AUTOSAR XML (schema 4-0-3)
package /ComponentTypes
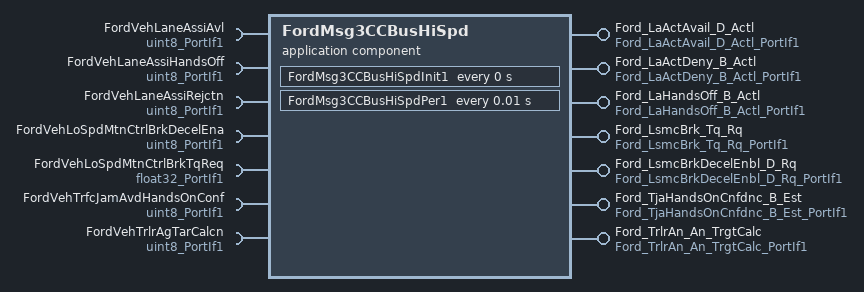
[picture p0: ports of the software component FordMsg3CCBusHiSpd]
  application sw component type FordMsg3CCBusHiSpd  # The purpose of the Ford Message 3CC Bus High Speed function is to transmit Electric Power Assisted Steering information to other vehicle modules
    7 x provide port:
      Ford_LaActAvail_D_Actl: nonqueued-sender-com-spec{data-element=Ford_LaActAvail_D_Actl, init-value=0}, provided-interface=Ford_LaActAvail_D_Actl_PortIf1  # Processed value of Ford_LaActAvail_D_Actl. Customer datatype should be used. Datatype:Ford_LaActAvail_D_Actl Elements are: 0 - "Cx0_LCA_LKA_LDW_Suppress", 1 - "Cx1_LCA_LKA_Suppress_LDW_Avail2 - "Cx2_LCA_LKA_Avail_LDW_Suppress", 3 - "Cx3_LKA_LCA_LDW_Avail"
      Ford_LaActDeny_B_Actl: nonqueued-sender-com-spec{data-element=Ford_LaActDeny_B_Actl, init-value=0}, provided-interface=Ford_LaActDeny_B_Actl_PortIf1  # Processed value of Ford_LaActDeny_B_Actl1. Customer datatype should be used. Datatype:Ford_LaActDeny_B_Actl. Elements are: 0 - "Cx0_LA_Not_Denied", 1 - "Cx1_LA_Denied
      Ford_LaHandsOff_B_Actl: nonqueued-sender-com-spec{data-element=Ford_LaHandsOff_B_Actl, init-value=1}, provided-interface=Ford_LaHandsOff_B_Actl_PortIf1  # Processed value of Ford_LaHandsOff_B_Actl. Customer datatype should be used. Datatype:Ford_LaHandsOff_B_Actl. Elements are: 0 - "Cx0_Hands_On", 1 - "Cx1_Hands_Off
      Ford_LsmcBrk_Tq_Rq: nonqueued-sender-com-spec{data-element=Ford_LsmcBrk_Tq_Rq, init-value=0}, provided-interface=Ford_LsmcBrk_Tq_Rq_PortIf1  # Processed value of Ford_LsmcBrk_Tq_Rq. Customer datatype should be used. Datatype:Ford_LsmcBrk_Tq_Rq with the range of 0 to 32764.
      Ford_LsmcBrkDecelEnbl_D_Rq: nonqueued-sender-com-spec{data-element=Ford_LsmcBrkDecelEnbl_D_Rq, init-value=0}, provided-interface=Ford_LsmcBrkDecelEnbl_D_Rq_PortIf1  # Processed value of Ford_LsmcBrkDecelEnbl_D_Rq. Customer datatype should be used. Datatype:Ford_LsmcBrkDecelEnbl_D_Rq. Elements are: 0 - "Cx0' _Off", 1 - "Cx1_On2 - "Cx2_NotUsed1", 3 - "Cx3_NotUsed2
      Ford_TjaHandsOnCnfdnc_B_Est: nonqueued-sender-com-spec{data-element=Ford_TjaHandsOnCnfdnc_B_Est, init-value=0}, provided-interface=Ford_TjaHandsOnCnfdnc_B_Est_PortIf1  # Processed value of Ford_TjaHandsOnCnfdnc_B_Est.Customer datatype should be used. Datatype:Ford_TjaHandsOnCnfdnc_B_Est1. Elements are: 0 - "C' x0_Low_Confidence", 1 - "Cx1_High_Confidence
      Ford_TrlrAn_An_TrgtCalc: nonqueued-sender-com-spec{data-element=Ford_TrlrAn_An_TrgtCalc, init-value=0}, provided-interface=Ford_TrlrAn_An_TrgtCalc_PortIf1  # Processed value of Ford_TrlrAn_An_TrgtCalc.Customer datatype should be used. Datatype:Ford_TrlrAn_An_TrgtCalc with the range of 0 to 255.
    7 x require port:
      FordVehLaneAssiAvl: nonqueued-receiver-com-spec{data-element=Val, filter=data-filter-type=ALWAYS, init-value=0}, required-interface=uint8_PortIf1  # Ford Vehicle Lane Assist Available is received as input from EPS and processed to CAN Bus
      FordVehLaneAssiHandsOff: nonqueued-receiver-com-spec{data-element=Val, filter=data-filter-type=ALWAYS, init-value=1}, required-interface=uint8_PortIf1  # Ford Vehicle Lane Assist Hands Off is received as input from EPS and processed to CAN Bus
      FordVehLaneAssiRejctn: nonqueued-receiver-com-spec{data-element=Val, filter=data-filter-type=ALWAYS, init-value=0}, required-interface=uint8_PortIf1  # Ford Vehicle Lane Assist Rejection is received as input from EPS and processed to CAN Bus
      FordVehLoSpdMtnCtrlBrkDecelEna: nonqueued-receiver-com-spec{data-element=Val, filter=data-filter-type=ALWAYS, init-value=0}, required-interface=uint8_PortIf1  # Ford Vehicle Low Speed Motion Control Brake Deceleration Enable is received as input from EPS and processed to CAN Bus
      FordVehLoSpdMtnCtrlBrkTqReq: nonqueued-receiver-com-spec{data-element=Val, filter=data-filter-type=ALWAYS, init-value=0}, required-interface=float32_PortIf1  # Ford Vehicle Low Speed Motion Control Brake Torque Request is received as input from EPS and processed to CAN Bus
      FordVehTrfcJamAvdHandsOnConf: nonqueued-receiver-com-spec{data-element=Val, filter=data-filter-type=ALWAYS, init-value=0}, required-interface=uint8_PortIf1  # Ford Vehicle Traffic Jam Avoidance Hands On Confidence is received as input from EPS and processed to CAN Bus
      FordVehTrlrAgTarCalcn: nonqueued-receiver-com-spec{data-element=Val, filter=data-filter-type=ALWAYS, init-value=0}, required-interface=uint8_PortIf1  # Ford Vehicle Trailer Angle Target Calculation is received as input from EPS and processed to CAN Bus
    behavior FordMsg3CCBusHiSpd_InternalBehavior
      timing event FordMsg3CCBusHiSpd_InitEvent: start-on-event=FordMsg3CCBusHiSpdInit1, period=0
      timing event TMT_FordMsg3CCBusHiSpdPer1: start-on-event=FordMsg3CCBusHiSpdPer1, period=0.01
      runnable FordMsg3CCBusHiSpdInit1  # Initialization Runnable
        data-send-points:
          access SEND_Ford_LaHandsOff_B_Actl_Ford_LaHandsOff_B_Actl: accessed-variable=Ford_LaHandsOff_B_Actl.Ford_LaHandsOff_B_Actl
      runnable FordMsg3CCBusHiSpdPer1: minimum-start-interval=0.01  # Periodic Runnable at 10ms
        data-receive-point-by-arguments:
          7 x access:
            REC_FordVehLaneAssiAvl_Val: accessed-variable=FordVehLaneAssiAvl.Val
            REC_FordVehLaneAssiHandsOff_Val: accessed-variable=FordVehLaneAssiHandsOff.Val
            REC_FordVehLaneAssiRejctn_Val: accessed-variable=FordVehLaneAssiRejctn.Val
            REC_FordVehLoSpdMtnCtrlBrkDecelEna_Val: accessed-variable=FordVehLoSpdMtnCtrlBrkDecelEna.Val
            REC_FordVehLoSpdMtnCtrlBrkTqReq_Val: accessed-variable=FordVehLoSpdMtnCtrlBrkTqReq.Val
            REC_FordVehTrfcJamAvdHandsOnConf_Val: accessed-variable=FordVehTrfcJamAvdHandsOnConf.Val
            REC_FordVehTrlrAgTarCalcn_Val: accessed-variable=FordVehTrlrAgTarCalcn.Val
        data-send-points:
          7 x access:
            SEND_Ford_LaActAvail_D_Actl1_Ford_LaActAvail_D_Actl: accessed-variable=Ford_LaActAvail_D_Actl.Ford_LaActAvail_D_Actl
            SEND_Ford_LaActDeny_B_Actl1_Ford_LaActDeny_B_Actl: accessed-variable=Ford_LaActDeny_B_Actl.Ford_LaActDeny_B_Actl
            SEND_Ford_LaHandsOff_B_Actl1_Ford_LaHandsOff_B_Actl: accessed-variable=Ford_LaHandsOff_B_Actl.Ford_LaHandsOff_B_Actl
            SEND_Ford_LsmcBrk_Tq_Rq_Ford_LsmcBrk_Tq_Rq: accessed-variable=Ford_LsmcBrk_Tq_Rq.Ford_LsmcBrk_Tq_Rq
            SEND_Ford_LsmcBrkDecelEnbl_D_Rq1_Ford_LsmcBrkDecelEnbl_D_Rq: accessed-variable=Ford_LsmcBrkDecelEnbl_D_Rq.Ford_LsmcBrkDecelEnbl_D_Rq
            SEND_Ford_TjaHandsOnCnfdnc_B_Est1_Ford_TjaHandsOnCnfdnc_B_Est: accessed-variable=Ford_TjaHandsOnCnfdnc_B_Est.Ford_TjaHandsOnCnfdnc_B_Est
            SEND_Ford_TrlrAn_An_TrgtCalc_Ford_TrlrAn_An_TrgtCalc: accessed-variable=Ford_TrlrAn_An_TrgtCalc.Ford_TrlrAn_An_TrgtCalc
  swc implementation FordMsg3CCBusHiSpd_Implementation: behavior=FordMsg3CCBusHiSpd_InternalBehavior
    code-descriptors:
      code Default: artifact-descriptors=autosar-engineering-object={short-label=Default, category=SWSRC}
